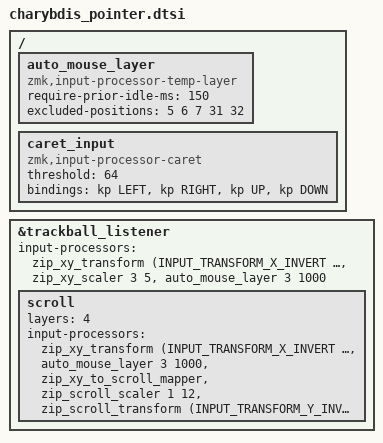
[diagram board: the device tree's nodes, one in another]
#include <input/processors.dtsi>
#include <dt-bindings/zmk/keys.h>
#include <dt-bindings/zmk/input_transform.h>

&trackball_listener {
    /*
     * The sensor is mounted mirrored on both axes relative to how ZMK expects
     * it, so up read as down and left read as right. Invert both before any
     * other processing, so every downstream consumer sees correct motion.
     */
    input-processors = <
        &zip_xy_transform (INPUT_TRANSFORM_X_INVERT | INPUT_TRANSFORM_Y_INVERT)
        &zip_xy_scaler 3 5
        &auto_mouse_layer 3 1000
    >;

    /*
     * Hold L on the MOUSE layer to get here. Trackball motion becomes scroll
     * wheel instead of pointer movement, like holding a middle mouse button.
     * The xy transform runs first so scrolling starts from corrected motion.
     * zip_scroll_scaler is the knob if it scrolls too fast or too slow, and
     * dropping the Y_INVERT below flips scroll direction.
     */
    scroll: scroll {
        layers = <4>;
        input-processors = <
            &zip_xy_transform (INPUT_TRANSFORM_X_INVERT | INPUT_TRANSFORM_Y_INVERT)
            &auto_mouse_layer 3 1000
            &zip_xy_to_scroll_mapper
            &zip_scroll_scaler 1 12
            &zip_scroll_transform (INPUT_TRANSFORM_Y_INVERT)
        >;
    };
};

/ {
    /*
     * Moving the trackball turns on the MOUSE layer (3) and it drops 1000ms
     * after the last motion.
     *
     * excluded-positions lists keys that do NOT deactivate the layer:
     *   5, 6, 7   the mouse buttons themselves, or the first click would
     *             cancel the layer before it registered
     *   31, 32    left thumb shift and ctrl, so shift-click and ctrl-click work
     * Everything else drops the layer the moment you press it, so going back
     * to typing is immediate.
     *
     * require-prior-idle-ms stops the layer arming within 150ms of a keystroke,
     * so brushing the ball mid-word does not turn J/L/U into clicks. Raise it
     * if that still happens, lower it toward 0 if the layer feels sluggish.
     */
    auto_mouse_layer: auto_mouse_layer {
        compatible = "zmk,input-processor-temp-layer";
        #input-processor-cells = <2>;
        require-prior-idle-ms = <150>;
        excluded-positions = <5 6 7 31 32>;
    };

    caret_input: caret_input {
        compatible = "zmk,input-processor-caret";
        #input-processor-cells = <0>;
        threshold = <64>;
        bindings = <&kp LEFT>, <&kp RIGHT>, <&kp UP>, <&kp DOWN>;
    };
};
